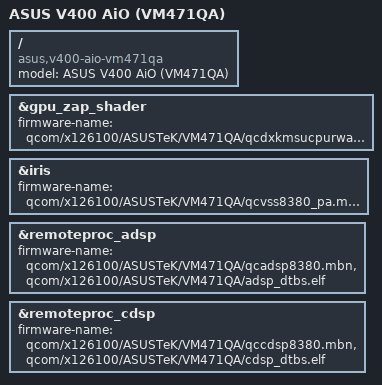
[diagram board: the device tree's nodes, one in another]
// SPDX-License-Identifier: BSD-3-Clause
/*
 * Copyright (c) 2026, Birk Skyum <birk.skyum@pm.me>
 */

/dts-v1/;

#include "x126100-asus-v400-aio.dtsi"

/ {
	model = "ASUS V400 AiO (VM471QA)";
	compatible = "asus,v400-aio-vm471qa", "qcom,x126100", "qcom,x1p42100";
};

&gpu_zap_shader {
	firmware-name = "qcom/x126100/ASUSTeK/VM471QA/qcdxkmsucpurwa.mbn";
};

&iris {
	firmware-name = "qcom/x126100/ASUSTeK/VM471QA/qcvss8380_pa.mbn";
};

&remoteproc_adsp {
	firmware-name = "qcom/x126100/ASUSTeK/VM471QA/qcadsp8380.mbn",
			"qcom/x126100/ASUSTeK/VM471QA/adsp_dtbs.elf";
};

&remoteproc_cdsp {
	firmware-name = "qcom/x126100/ASUSTeK/VM471QA/qccdsp8380.mbn",
			"qcom/x126100/ASUSTeK/VM471QA/cdsp_dtbs.elf";
};
